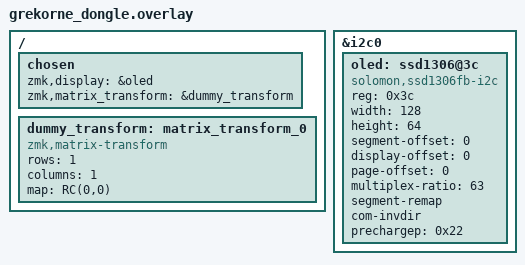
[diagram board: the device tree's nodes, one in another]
#include <dt-bindings/zmk/matrix_transform.h>
#include <dt-bindings/zmk/physical_layout.h>

/ {
    chosen {
        zmk,display = &oled;
        zmk,matrix_transform = &dummy_transform;
    };

    dummy_transform: matrix_transform_0 {
        compatible = "zmk,matrix-transform";
        rows = <1>;
        columns = <1>;
        map = <RC(0,0)>;
    };
};

&i2c0 {
    status = "okay";

    oled: ssd1306@3c {
        compatible = "solomon,ssd1306fb-i2c";
        reg = <0x3c>;

        width = <128>;
        height = <64>;

        segment-offset = <0>;
        display-offset = <0>;
        page-offset = <0>;

        multiplex-ratio = <63>;

        segment-remap;
        com-invdir;

        prechargep = <0x22>;
    };
};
